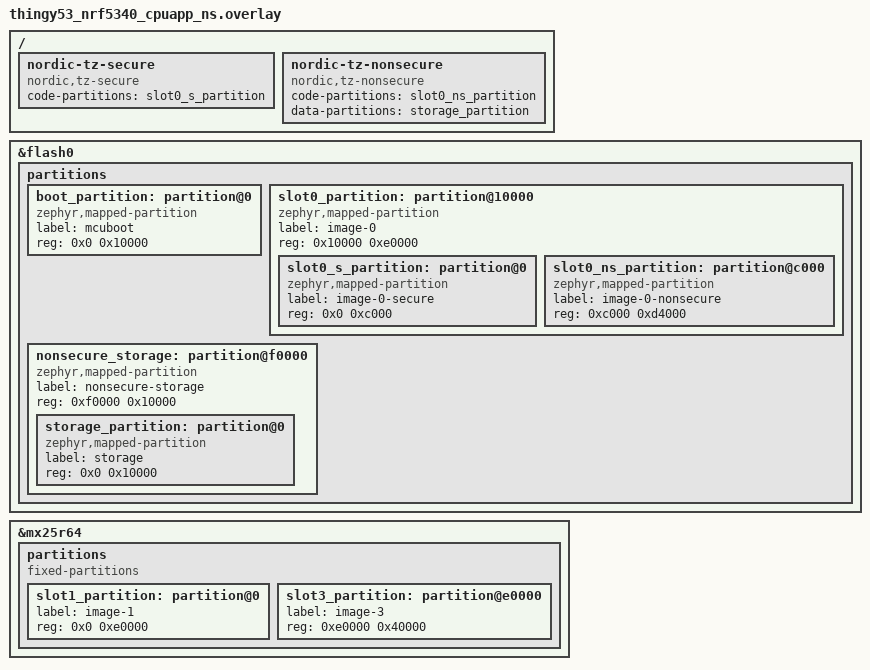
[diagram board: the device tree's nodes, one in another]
/*
 * Copyright (c) 2026 Nordic Semiconductor ASA
 *
 * SPDX-License-Identifier: LicenseRef-Nordic-5-Clause
 *
 * Memory map for split image with network core update.
 * External slots: slot1 = app secondary, slot3 = netcore secondary.
 */

/delete-node/ &boot_partition;
/delete-node/ &slot0_partition;
/delete-node/ &slot1_partition;
/delete-node/ &tfm_ps_partition;
/delete-node/ &tfm_its_partition;
/delete-node/ &tfm_otp_partition;
/delete-node/ &storage_partition;

&flash0 {
	partitions {
		boot_partition: partition@0 {
			compatible = "zephyr,mapped-partition";
			label = "mcuboot";
			reg = <0x0 0x10000>;
		};

		slot0_partition: partition@10000 {
			compatible = "zephyr,mapped-partition";
			label = "image-0";
			reg = <0x10000 0xe0000>;
			ranges = <0x0 0x10000 0xe0000>;
			#address-cells = <1>;
			#size-cells = <1>;

			slot0_s_partition: partition@0 {
				compatible = "zephyr,mapped-partition";
				label = "image-0-secure";
				reg = <0x0 0xc000>;
			};

			slot0_ns_partition: partition@c000 {
				compatible = "zephyr,mapped-partition";
				label = "image-0-nonsecure";
				reg = <0xc000 0xd4000>;
			};
		};

		nonsecure_storage: partition@f0000 {
			compatible = "zephyr,mapped-partition";
			label = "nonsecure-storage";
			reg = <0xf0000 0x10000>;
			ranges = <0x0 0xf0000 0x10000>;
			#address-cells = <1>;
			#size-cells = <1>;

			storage_partition: partition@0 {
				compatible = "zephyr,mapped-partition";
				label = "storage";
				reg = <0x0 0x10000>;
			};
		};
	};
};

&mx25r64 {
	status = "okay";

	partitions {
		compatible = "fixed-partitions";
		#address-cells = <1>;
		#size-cells = <1>;

		slot1_partition: partition@0 {
			label = "image-1";
			reg = <0x0 0xe0000>;
		};

		slot3_partition: partition@e0000 {
			label = "image-3";
			reg = <0xe0000 0x40000>;
		};
	};
};

/ {
	/delete-node/ nordic-tz-secure;
	/delete-node/ nordic-tz-nonsecure;

	nordic-tz-secure {
		compatible = "nordic,tz-secure";
		code-partitions = <&slot0_s_partition>;
	};

	nordic-tz-nonsecure {
		compatible = "nordic,tz-nonsecure";
		code-partitions = <&slot0_ns_partition>;
		data-partitions = <&storage_partition>;
	};
};
